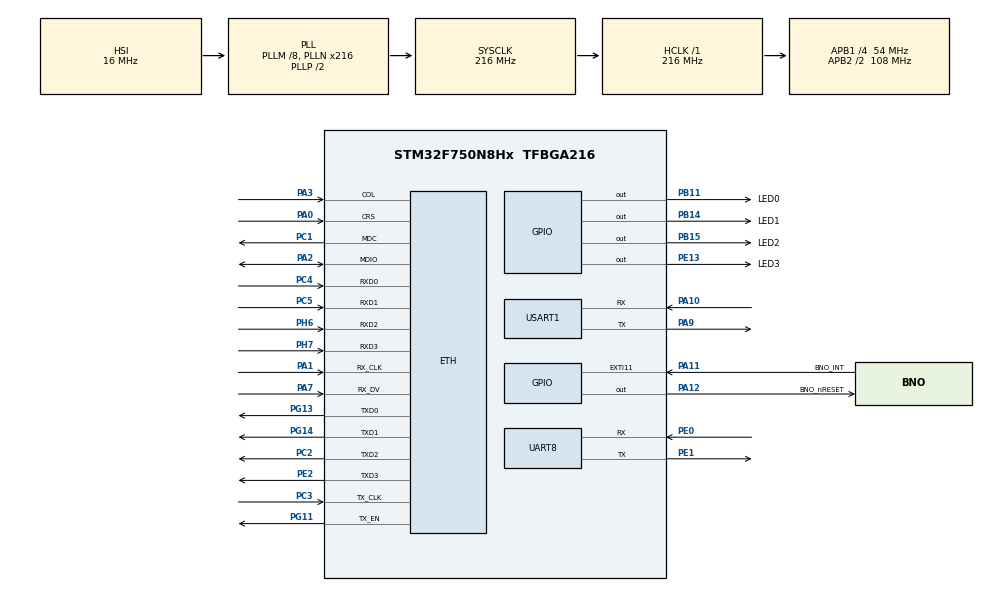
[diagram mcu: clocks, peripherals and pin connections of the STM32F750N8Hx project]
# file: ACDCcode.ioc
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ETH.MediaInterface=ETH_MEDIA_INTERFACE_MII
Mcu.Family=STM32F7
Mcu.Name=STM32F750N8Hx
Mcu.Package=TFBGA216
NVIC.EXTI15_10_IRQn=true\:0\:0\:false\:false\:true\:true\:true
NVIC.PriorityGroup=NVIC_PRIORITYGROUP_4
NVIC.TIM3_IRQn=true\:0\:0\:false\:false\:true\:true\:true
NVIC.USART1_IRQn=true\:0\:0\:false\:false\:true\:true\:true
PA0/WKUP.Mode=MII
PA0/WKUP.Signal=ETH_CRS
PA1.Mode=MII
PA1.Signal=ETH_RX_CLK
PA10.Mode=Asynchronous
PA10.Signal=USART1_RX
PA11.GPIO_Label=BNO_INT
PA11.Signal=GPXTI11
PA12.GPIO_Label=BNO_nRESET
PA12.PinState=GPIO_PIN_SET
PA12.Signal=GPIO_Output
PA13.Mode=Trace_Asynchronous_SW
PA13.Signal=SYS_JTMS-SWDIO
PA14.Mode=Trace_Asynchronous_SW
PA14.Signal=SYS_JTCK-SWCLK
PA2.Mode=MII
PA2.Signal=ETH_MDIO
PA3.Mode=MII
PA3.Signal=ETH_COL
PA7.Mode=MII
PA7.Signal=ETH_RX_DV
PA9.Mode=Asynchronous
PA9.Signal=USART1_TX
PB11.GPIO_Label=LED0
PB11.PinState=GPIO_PIN_RESET
PB11.Signal=GPIO_Output
PB14.GPIO_Label=LED1
PB14.Signal=GPIO_Output
PB15.GPIO_Label=LED2
PB15.PinState=GPIO_PIN_SET
PB15.Signal=GPIO_Output
PB3.Mode=Trace_Asynchronous_SW
PB3.Signal=SYS_JTDO-SWO
PC1.Mode=MII
PC1.Signal=ETH_MDC
PC2.Mode=MII
PC2.Signal=ETH_TXD2
PC3.Mode=MII
PC3.Signal=ETH_TX_CLK
PC4.Mode=MII
PC4.Signal=ETH_RXD0
PC5.Mode=MII
PC5.Signal=ETH_RXD1
PE0.Mode=Asynchronous
PE0.Signal=UART8_RX
PE1.Mode=Asynchronous
PE1.Signal=UART8_TX
PE13.GPIO_Label=LED3
PE13.Signal=GPIO_Output
PE2.Mode=MII
PE2.Signal=ETH_TXD3
PG11.Mode=MII
PG11.Signal=ETH_TX_EN
PG13.Mode=MII
PG13.Signal=ETH_TXD0
PG14.Mode=MII
PG14.Signal=ETH_TXD1
PH6.Mode=MII
PH6.Signal=ETH_RXD2
PH7.Mode=MII
PH7.Signal=ETH_RXD3
ProjectManager.HeapSize=0x200
ProjectManager.StackSize=0x400
ProjectManager.TargetToolchain=STM32CubeIDE
RCC.AHBFreq_Value=216000000
RCC.APB1CLKDivider=RCC_HCLK_DIV4
RCC.APB1Freq_Value=54000000
RCC.APB1TimFreq_Value=108000000
RCC.APB2CLKDivider=RCC_HCLK_DIV2
RCC.APB2Freq_Value=108000000
RCC.APB2TimFreq_Value=216000000
RCC.CortexFreq_Value=216000000
RCC.HCLKFreq_Value=216000000
RCC.HSE_VALUE=25000000
RCC.HSI_VALUE=16000000
RCC.LSE_VALUE=32768
RCC.PLLM=8
RCC.PLLN=216
RCC.SYSCLKFreq_VALUE=216000000
RCC.SYSCLKSource=RCC_SYSCLKSOURCE_PLLCLK
RCC.USBFreq_Value=216000000
RCC.VCOOutputFreq_Value=432000000
TIM3.Period=21599
TIM3.Prescaler=999
USART1.VirtualMode-Asynchronous=VM_ASYNC
VP_TIM3_VS_ClockSourceINT.Mode=Internal
board=custom

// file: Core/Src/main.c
/* USER CODE BEGIN Header */
/**
  ******************************************************************************
  * @file           : main.c
  * @brief          : Main program body
  ******************************************************************************
  * @attention
  *
  * <h2><center>&copy; Copyright (c) 2021 STMicroelectronics.
  * All rights reserved.</center></h2>
  *
  * This software component is licensed by ST under BSD 3-Clause license,
  * the "License"; You may not use this file except in compliance with the
  * License. You may obtain a copy of the License at:
  *                        opensource.org/licenses/BSD-3-Clause
  *
  ******************************************************************************
  */
/* USER CODE END Header */
#include "main.h"

ETH_HandleTypeDef heth;

TIM_HandleTypeDef htim3;

UART_HandleTypeDef huart8;
UART_HandleTypeDef huart1;

void SystemClock_Config(void);
static void MX_GPIO_Init(void);
static void MX_ETH_Init(void);
static void MX_UART8_Init(void);
static void MX_USART1_UART_Init(void);
static void MX_TIM3_Init(void);

int main(void)
{

  /* MCU Configuration--------------------------------------------------------*/

  /* Reset of all peripherals, Initializes the Flash interface and the Systick. */
  HAL_Init();

  /* Configure the system clock */
  SystemClock_Config();

  /* Initialize all configured peripherals */
  MX_GPIO_Init();
  MX_ETH_Init();
  MX_UART8_Init();
  MX_USART1_UART_Init();
  MX_TIM3_Init();
  /* USER CODE BEGIN 2 */
  HAL_TIM_Base_Start_IT(&htim3);

  /* USER CODE END 2 */

  /* Infinite loop */
  while (1)
  {

  }
}

void SystemClock_Config(void)
{
  RCC_OscInitTypeDef RCC_OscInitStruct = {0};
  RCC_ClkInitTypeDef RCC_ClkInitStruct = {0};
  RCC_PeriphCLKInitTypeDef PeriphClkInitStruct = {0};

  /** Configure the main internal regulator output voltage
  */
  __HAL_RCC_PWR_CLK_ENABLE();
  __HAL_PWR_VOLTAGESCALING_CONFIG(PWR_REGULATOR_VOLTAGE_SCALE1);
  /** Initializes the RCC Oscillators according to the specified parameters
  * in the RCC_OscInitTypeDef structure.
  */
  RCC_OscInitStruct.OscillatorType = RCC_OSCILLATORTYPE_HSI;
  RCC_OscInitStruct.HSIState = RCC_HSI_ON;
  RCC_OscInitStruct.HSICalibrationValue = RCC_HSICALIBRATION_DEFAULT;
  RCC_OscInitStruct.PLL.PLLState = RCC_PLL_ON;
  RCC_OscInitStruct.PLL.PLLSource = RCC_PLLSOURCE_HSI;
  RCC_OscInitStruct.PLL.PLLM = 8;
  RCC_OscInitStruct.PLL.PLLN = 216;
  RCC_OscInitStruct.PLL.PLLP = RCC_PLLP_DIV2;
  RCC_OscInitStruct.PLL.PLLQ = 2;
  if (HAL_RCC_OscConfig(&RCC_OscInitStruct) != HAL_OK)
  {
    Error_Handler();
  }
  /** Activate the Over-Drive mode
  */
  if (HAL_PWREx_EnableOverDrive() != HAL_OK)
  {
    Error_Handler();
  }
  /** Initializes the CPU, AHB and APB buses clocks
  */
  RCC_ClkInitStruct.ClockType = RCC_CLOCKTYPE_HCLK|RCC_CLOCKTYPE_SYSCLK
                              |RCC_CLOCKTYPE_PCLK1|RCC_CLOCKTYPE_PCLK2;
  RCC_ClkInitStruct.SYSCLKSource = RCC_SYSCLKSOURCE_PLLCLK;
  RCC_ClkInitStruct.AHBCLKDivider = RCC_SYSCLK_DIV1;
  RCC_ClkInitStruct.APB1CLKDivider = RCC_HCLK_DIV4;
  RCC_ClkInitStruct.APB2CLKDivider = RCC_HCLK_DIV2;

  if (HAL_RCC_ClockConfig(&RCC_ClkInitStruct, FLASH_LATENCY_7) != HAL_OK)
  {
    Error_Handler();
  }
  PeriphClkInitStruct.PeriphClockSelection = RCC_PERIPHCLK_USART1|RCC_PERIPHCLK_UART8;
  PeriphClkInitStruct.Usart1ClockSelection = RCC_USART1CLKSOURCE_PCLK2;
  PeriphClkInitStruct.Uart8ClockSelection = RCC_UART8CLKSOURCE_PCLK1;
  if (HAL_RCCEx_PeriphCLKConfig(&PeriphClkInitStruct) != HAL_OK)
  {
    Error_Handler();
  }
}

static void MX_ETH_Init(void)
{

   static uint8_t MACAddr[6];

  heth.Instance = ETH;
  heth.Init.AutoNegotiation = ETH_AUTONEGOTIATION_ENABLE;
  heth.Init.Speed = ETH_SPEED_100M;
  heth.Init.DuplexMode = ETH_MODE_FULLDUPLEX;
  heth.Init.PhyAddress = DP83848_PHY_ADDRESS;
  MACAddr[0] = 0x00;
  MACAddr[1] = 0x80;
  MACAddr[2] = 0xE1;
  MACAddr[3] = 0x00;
  MACAddr[4] = 0x00;
  MACAddr[5] = 0x00;
  heth.Init.MACAddr = &MACAddr[0];
  heth.Init.RxMode = ETH_RXPOLLING_MODE;
  heth.Init.ChecksumMode = ETH_CHECKSUM_BY_HARDWARE;
  heth.Init.MediaInterface = ETH_MEDIA_INTERFACE_MII;

  if (HAL_ETH_Init(&heth) != HAL_OK)
  {
    Error_Handler();
  }

}

static void MX_TIM3_Init(void)
{

  TIM_ClockConfigTypeDef sClockSourceConfig = {0};
  TIM_MasterConfigTypeDef sMasterConfig = {0};

  htim3.Instance = TIM3;
  htim3.Init.Prescaler = 999;
  htim3.Init.CounterMode = TIM_COUNTERMODE_UP;
  htim3.Init.Period = 21599;
  htim3.Init.ClockDivision = TIM_CLOCKDIVISION_DIV1;
  htim3.Init.AutoReloadPreload = TIM_AUTORELOAD_PRELOAD_DISABLE;
  if (HAL_TIM_Base_Init(&htim3) != HAL_OK)
  {
    Error_Handler();
  }
  sClockSourceConfig.ClockSource = TIM_CLOCKSOURCE_INTERNAL;
  if (HAL_TIM_ConfigClockSource(&htim3, &sClockSourceConfig) != HAL_OK)
  {
    Error_Handler();
  }
  sMasterConfig.MasterOutputTrigger = TIM_TRGO_RESET;
  sMasterConfig.MasterSlaveMode = TIM_MASTERSLAVEMODE_DISABLE;
  if (HAL_TIMEx_MasterConfigSynchronization(&htim3, &sMasterConfig) != HAL_OK)
  {
    Error_Handler();
  }

}

static void MX_UART8_Init(void)
{

  huart8.Instance = UART8;
  huart8.Init.BaudRate = 115200;
  huart8.Init.WordLength = UART_WORDLENGTH_8B;
  huart8.Init.StopBits = UART_STOPBITS_1;
  huart8.Init.Parity = UART_PARITY_NONE;
  huart8.Init.Mode = UART_MODE_TX_RX;
  huart8.Init.HwFlowCtl = UART_HWCONTROL_NONE;
  huart8.Init.OverSampling = UART_OVERSAMPLING_16;
  huart8.Init.OneBitSampling = UART_ONE_BIT_SAMPLE_DISABLE;
  huart8.AdvancedInit.AdvFeatureInit = UART_ADVFEATURE_NO_INIT;
  if (HAL_UART_Init(&huart8) != HAL_OK)
  {
    Error_Handler();
  }

}

static void MX_USART1_UART_Init(void)
{

  huart1.Instance = USART1;
  huart1.Init.BaudRate = 115200;
  huart1.Init.WordLength = UART_WORDLENGTH_8B;
  huart1.Init.StopBits = UART_STOPBITS_1;
  huart1.Init.Parity = UART_PARITY_NONE;
  huart1.Init.Mode = UART_MODE_TX_RX;
  huart1.Init.HwFlowCtl = UART_HWCONTROL_NONE;
  huart1.Init.OverSampling = UART_OVERSAMPLING_16;
  huart1.Init.OneBitSampling = UART_ONE_BIT_SAMPLE_DISABLE;
  huart1.AdvancedInit.AdvFeatureInit = UART_ADVFEATURE_NO_INIT;
  if (HAL_UART_Init(&huart1) != HAL_OK)
  {
    Error_Handler();
  }

}

static void MX_GPIO_Init(void)
{
  GPIO_InitTypeDef GPIO_InitStruct = {0};

  /* GPIO Ports Clock Enable */
  __HAL_RCC_GPIOE_CLK_ENABLE();
  __HAL_RCC_GPIOG_CLK_ENABLE();
  __HAL_RCC_GPIOB_CLK_ENABLE();
  __HAL_RCC_GPIOA_CLK_ENABLE();
  __HAL_RCC_GPIOC_CLK_ENABLE();
  __HAL_RCC_GPIOH_CLK_ENABLE();

  /*Configure GPIO pin Output Level */
  HAL_GPIO_WritePin(BNO_nRESET_GPIO_Port, BNO_nRESET_Pin, GPIO_PIN_SET);

  /*Configure GPIO pin Output Level */
  HAL_GPIO_WritePin(LED3_GPIO_Port, LED3_Pin, GPIO_PIN_RESET);

  /*Configure GPIO pin Output Level */
  HAL_GPIO_WritePin(GPIOB, LED0_Pin|LED1_Pin, GPIO_PIN_RESET);

  /*Configure GPIO pin Output Level */
  HAL_GPIO_WritePin(LED2_GPIO_Port, LED2_Pin, GPIO_PIN_SET);

  /*Configure GPIO pin : BNO_nRESET_Pin */
  GPIO_InitStruct.Pin = BNO_nRESET_Pin;
  GPIO_InitStruct.Mode = GPIO_MODE_OUTPUT_PP;
  GPIO_InitStruct.Pull = GPIO_NOPULL;
  GPIO_InitStruct.Speed = GPIO_SPEED_FREQ_LOW;
  HAL_GPIO_Init(BNO_nRESET_GPIO_Port, &GPIO_InitStruct);

  /*Configure GPIO pin : BNO_INT_Pin */
  GPIO_InitStruct.Pin = BNO_INT_Pin;
  GPIO_InitStruct.Mode = GPIO_MODE_IT_RISING;
  GPIO_InitStruct.Pull = GPIO_NOPULL;
  HAL_GPIO_Init(BNO_INT_GPIO_Port, &GPIO_InitStruct);

  /*Configure GPIO pin : LED3_Pin */
  GPIO_InitStruct.Pin = LED3_Pin;
  GPIO_InitStruct.Mode = GPIO_MODE_OUTPUT_PP;
  GPIO_InitStruct.Pull = GPIO_NOPULL;
  GPIO_InitStruct.Speed = GPIO_SPEED_FREQ_LOW;
  HAL_GPIO_Init(LED3_GPIO_Port, &GPIO_InitStruct);

  /*Configure GPIO pins : LED0_Pin LED1_Pin LED2_Pin */
  GPIO_InitStruct.Pin = LED0_Pin|LED1_Pin|LED2_Pin;
  GPIO_InitStruct.Mode = GPIO_MODE_OUTPUT_PP;
  GPIO_InitStruct.Pull = GPIO_NOPULL;
  GPIO_InitStruct.Speed = GPIO_SPEED_FREQ_LOW;
  HAL_GPIO_Init(GPIOB, &GPIO_InitStruct);

  /* EXTI interrupt init*/
  HAL_NVIC_SetPriority(EXTI15_10_IRQn, 0, 0);
  HAL_NVIC_EnableIRQ(EXTI15_10_IRQn);

}

/* USER CODE BEGIN 4 */
void TIM3_IRQHandler(void)
{
  HAL_TIM_IRQHandler(&htim3);
}

void HAL_TIM_PeriodElapsedCallback(TIM_HandleTypeDef* htim)
{
// insert send to PI
}

void HAL_GPIO_EXTI_Callback(uint16_t GPIO_Pin)
{
    if(GPIO_Pin == GPIO_PIN_11) // If The INT Source Is EXTI Line9 (A9 Pin)
    {
  // Insert BNO PULL
    }
}

/* USER CODE END 4 */

void Error_Handler(void)
{
  __disable_irq();
  while (1)
  {
  }
}

/************************ (C) COPYRIGHT STMicroelectronics *****END OF FILE****/
